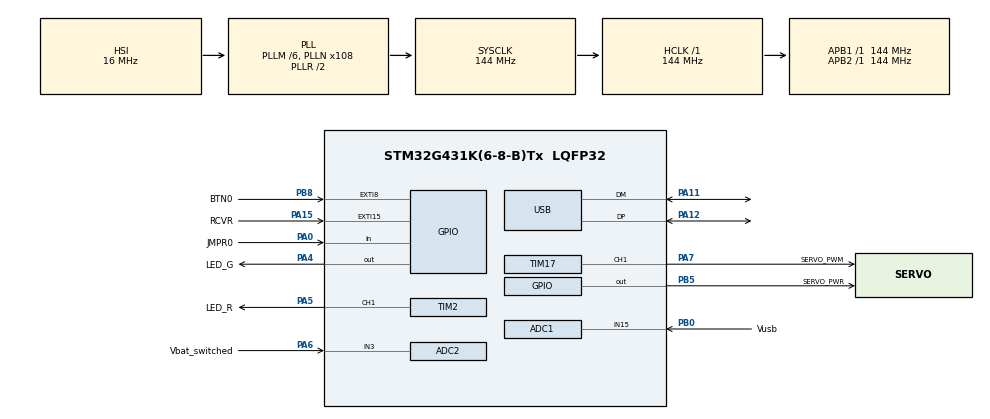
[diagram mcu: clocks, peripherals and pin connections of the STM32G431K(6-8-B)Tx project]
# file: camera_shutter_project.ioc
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ADC1.Channel-0\#ChannelRegularConversion=ADC_CHANNEL_15
ADC1.NbrOfConversionFlag=1
ADC1.OffsetNumber-0\#ChannelRegularConversion=ADC_OFFSET_NONE
ADC1.Rank-0\#ChannelRegularConversion=1
ADC1.SamplingTime-0\#ChannelRegularConversion=ADC_SAMPLETIME_2CYCLES_5
ADC1.master=1
ADC2.Channel-0\#ChannelRegularConversion=ADC_CHANNEL_3
ADC2.ClockPrescaler=ADC_CLOCK_SYNC_PCLK_DIV4
ADC2.NbrOfConversionFlag=1
ADC2.OffsetNumber-0\#ChannelRegularConversion=ADC_OFFSET_NONE
ADC2.Rank-0\#ChannelRegularConversion=1
ADC2.SamplingTime-0\#ChannelRegularConversion=ADC_SAMPLETIME_2CYCLES_5
Mcu.Family=STM32G4
Mcu.Name=STM32G431K(6-8-B)Tx
Mcu.Package=LQFP32
NVIC.EXTI15_10_IRQn=true\:3\:0\:true\:false\:true\:true\:true
NVIC.EXTI9_5_IRQn=true\:4\:0\:true\:false\:true\:true\:true
NVIC.PriorityGroup=NVIC_PRIORITYGROUP_4
NVIC.TIM1_CC_IRQn=true\:1\:0\:true\:false\:true\:true\:true
NVIC.TIM1_UP_TIM16_IRQn=true\:2\:0\:true\:false\:true\:true\:true
NVIC.USB_LP_IRQn=true\:0\:0\:false\:false\:true\:false\:true
PA0.GPIO_Label=JMPR0
PA0.Signal=GPIO_Input
PA11.Mode=Device
PA11.Signal=USB_DM
PA12.Mode=Device
PA12.Signal=USB_DP
PA13.Mode=Serial_Wire
PA13.Signal=SYS_JTMS-SWDIO
PA14.Mode=Serial_Wire
PA14.Signal=SYS_JTCK-SWCLK
PA15.GPIO_Label=RCVR
PA15.GPIO_ModeDefaultEXTI=GPIO_MODE_IT_FALLING
PA15.Signal=GPXTI15
PA4.GPIO_Label=LED_G
PA4.Signal=GPIO_Output
PA5.GPIO_Label=LED_R
PA5.Signal=S_TIM2_CH1
PA6.GPIO_Label=Vbat_switched
PA6.Mode=IN3-Single-Ended
PA6.Signal=ADC2_IN3
PA7.GPIO_Label=SERVO_PWM
PA7.Signal=S_TIM17_CH1
PB0.GPIO_Label=Vusb
PB0.Mode=IN15-Single-Ended
PB0.Signal=ADC1_IN15
PB5.GPIO_Label=SERVO_PWR
PB5.Signal=GPIO_Output
PB8-BOOT0.GPIO_Label=BTN0
PB8-BOOT0.GPIO_PuPd=GPIO_PULLDOWN
PB8-BOOT0.Signal=GPXTI8
PF0-OSC_IN.Mode=HSE-External-Oscillator
PF0-OSC_IN.Signal=RCC_OSC_IN
PF1-OSC_OUT.Mode=HSE-External-Oscillator
PF1-OSC_OUT.Signal=RCC_OSC_OUT
ProjectManager.HeapSize=0x200
ProjectManager.StackSize=0x400
ProjectManager.TargetToolchain=STM32CubeIDE
RCC.ADC12Freq_Value=144000000
RCC.AHBFreq_Value=144000000
RCC.APB1Freq_Value=144000000
RCC.APB1TimFreq_Value=144000000
RCC.APB2Freq_Value=144000000
RCC.APB2TimFreq_Value=144000000
RCC.CortexFreq_Value=144000000
RCC.EXTERNAL_CLOCK_VALUE=12288000
RCC.HCLKFreq_Value=144000000
RCC.HSE_VALUE=24000000
RCC.HSI48_VALUE=48000000
RCC.HSI_VALUE=16000000
RCC.LSE_VALUE=32768
RCC.PLLM=RCC_PLLM_DIV6
RCC.PLLN=108
RCC.PLLQ=RCC_PLLQ_DIV6
RCC.SYSCLKFreq_VALUE=144000000
RCC.SYSCLKSource=RCC_SYSCLKSOURCE_PLLCLK
RCC.USBFreq_Value=48000000
RCC.VCOOutputFreq_Value=288000000
SH.S_TIM17_CH1.0=TIM17_CH1,PWM Generation1 CH1
SH.S_TIM2_CH1.0=TIM2_CH1,PWM Generation1 CH1
TIM1.Channel-Output\ Compare1\ No\ Output=TIM_CHANNEL_1
TIM1.PeriodNoDither=1001
TIM1.Prescaler=146
TIM1.PulseNoDither_1=200
TIM1.RepetitionCounter=63
TIM1.TIM_MasterOutputTrigger=TIM_TRGO_RESET
TIM1.TIM_MasterSlaveMode=TIM_MASTERSLAVEMODE_DISABLE
TIM17.Channel=TIM_CHANNEL_1
TIM17.PeriodNoDither=2040
TIM17.Prescaler=143
TIM17.PulseNoDither_1=549
TIM2.Channel-PWM\ Generation1\ CH1=TIM_CHANNEL_1
TIM2.PeriodNoDither=9999
TIM2.Prescaler=9999
TIM2.PulseNoDither_1=4999
USB_DEVICE.CLASS_NAME_FS=CDC
USB_DEVICE.USBD_SELF_POWERED=1
USB_DEVICE.VirtualMode=Cdc
USB_DEVICE.VirtualModeFS=Cdc_FS
VP_SYS_VS_DBSignals.Mode=DisableDeadBatterySignals
VP_TIM17_VS_ClockSourceINT.Mode=Enable_Timer
VP_TIM1_VS_ClockSourceINT.Mode=Internal
VP_TIM1_VS_OPM.Mode=OPM_bit
VP_TIM1_VS_no_output1.Mode=Output Compare1 No Output
VP_TIM2_VS_ClockSourceINT.Mode=Internal
VP_USB_DEVICE_VS_USB_DEVICE_CDC_FS.Mode=CDC_FS
board=custom

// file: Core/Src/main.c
/* USER CODE BEGIN Header */
/**
  ******************************************************************************
  * @file           : main.c
  * @brief          : Main program body
  ******************************************************************************
  * @attention
  *
  * <h2><center>&copy; Copyright (c) 2021 STMicroelectronics.
  * All rights reserved.</center></h2>
  *
  * This software component is licensed by ST under BSD 3-Clause license,
  * the "License"; You may not use this file except in compliance with the
  * License. You may obtain a copy of the License at:
  *                        opensource.org/licenses/BSD-3-Clause
  *
  ******************************************************************************
  */
/* USER CODE END Header */
#include "main.h"
#include "usb_device.h"

/* USER CODE BEGIN Includes */
#include "program_logic.h"
#include "battery_tracking.h"
/* USER CODE END Includes */

ADC_HandleTypeDef hadc1;
ADC_HandleTypeDef hadc2;

TIM_HandleTypeDef htim1;
TIM_HandleTypeDef htim2;
TIM_HandleTypeDef htim17;

void SystemClock_Config(void);
static void MX_GPIO_Init(void);
static void MX_TIM2_Init(void);
static void MX_ADC2_Init(void);
static void MX_TIM1_Init(void);
static void MX_TIM17_Init(void);
static void MX_ADC1_Init(void);

int main(void)
{

  /* MCU Configuration--------------------------------------------------------*/

  /* Reset of all peripherals, Initializes the Flash interface and the Systick. */
  HAL_Init();

  /* Configure the system clock */
  SystemClock_Config();

  /* Initialize all configured peripherals */
  MX_GPIO_Init();
  MX_TIM2_Init();
  MX_ADC2_Init();
  MX_USB_Device_Init();
  MX_TIM1_Init();
  MX_TIM17_Init();
  MX_ADC1_Init();
  /* USER CODE BEGIN 2 */
  ProgramLogicInit();
  /* USER CODE END 2 */

  /* Infinite loop */
  while (1)
  {

    /* USER CODE BEGIN 3 */
    static int i = 0;
    printf("loop iteration: %d\n\n", i);
    HAL_Delay(500);
    BatteryTrackingUpdate();
    i++;
    HAL_Delay(500);
  }
  /* USER CODE END 3 */
}

void SystemClock_Config(void)
{
  RCC_OscInitTypeDef RCC_OscInitStruct = {0};
  RCC_ClkInitTypeDef RCC_ClkInitStruct = {0};
  RCC_PeriphCLKInitTypeDef PeriphClkInit = {0};

  /** Configure the main internal regulator output voltage
  */
  HAL_PWREx_ControlVoltageScaling(PWR_REGULATOR_VOLTAGE_SCALE1);
  /** Initializes the RCC Oscillators according to the specified parameters
  * in the RCC_OscInitTypeDef structure.
  */
  RCC_OscInitStruct.OscillatorType = RCC_OSCILLATORTYPE_HSI;
  RCC_OscInitStruct.HSIState = RCC_HSI_ON;
  RCC_OscInitStruct.HSICalibrationValue = RCC_HSICALIBRATION_DEFAULT;
  RCC_OscInitStruct.PLL.PLLState = RCC_PLL_ON;
  RCC_OscInitStruct.PLL.PLLSource = RCC_PLLSOURCE_HSI;
  RCC_OscInitStruct.PLL.PLLM = RCC_PLLM_DIV6;
  RCC_OscInitStruct.PLL.PLLN = 108;
  RCC_OscInitStruct.PLL.PLLP = RCC_PLLP_DIV2;
  RCC_OscInitStruct.PLL.PLLQ = RCC_PLLQ_DIV6;
  RCC_OscInitStruct.PLL.PLLR = RCC_PLLR_DIV2;
  if (HAL_RCC_OscConfig(&RCC_OscInitStruct) != HAL_OK)
  {
    Error_Handler();
  }
  /** Initializes the CPU, AHB and APB buses clocks
  */
  RCC_ClkInitStruct.ClockType = RCC_CLOCKTYPE_HCLK|RCC_CLOCKTYPE_SYSCLK
                              |RCC_CLOCKTYPE_PCLK1|RCC_CLOCKTYPE_PCLK2;
  RCC_ClkInitStruct.SYSCLKSource = RCC_SYSCLKSOURCE_PLLCLK;
  RCC_ClkInitStruct.AHBCLKDivider = RCC_SYSCLK_DIV1;
  RCC_ClkInitStruct.APB1CLKDivider = RCC_HCLK_DIV1;
  RCC_ClkInitStruct.APB2CLKDivider = RCC_HCLK_DIV1;

  if (HAL_RCC_ClockConfig(&RCC_ClkInitStruct, FLASH_LATENCY_4) != HAL_OK)
  {
    Error_Handler();
  }
  /** Initializes the peripherals clocks
  */
  PeriphClkInit.PeriphClockSelection = RCC_PERIPHCLK_USB|RCC_PERIPHCLK_ADC12;
  PeriphClkInit.UsbClockSelection = RCC_USBCLKSOURCE_PLL;
  PeriphClkInit.Adc12ClockSelection = RCC_ADC12CLKSOURCE_SYSCLK;
  if (HAL_RCCEx_PeriphCLKConfig(&PeriphClkInit) != HAL_OK)
  {
    Error_Handler();
  }
}

static void MX_ADC1_Init(void)
{

  ADC_MultiModeTypeDef multimode = {0};
  ADC_ChannelConfTypeDef sConfig = {0};

  /** Common config
  */
  hadc1.Instance = ADC1;
  hadc1.Init.ClockPrescaler = ADC_CLOCK_SYNC_PCLK_DIV4;
  hadc1.Init.Resolution = ADC_RESOLUTION_12B;
  hadc1.Init.DataAlign = ADC_DATAALIGN_RIGHT;
  hadc1.Init.GainCompensation = 0;
  hadc1.Init.ScanConvMode = ADC_SCAN_DISABLE;
  hadc1.Init.EOCSelection = ADC_EOC_SINGLE_CONV;
  hadc1.Init.LowPowerAutoWait = DISABLE;
  hadc1.Init.ContinuousConvMode = DISABLE;
  hadc1.Init.NbrOfConversion = 1;
  hadc1.Init.DiscontinuousConvMode = DISABLE;
  hadc1.Init.ExternalTrigConv = ADC_SOFTWARE_START;
  hadc1.Init.ExternalTrigConvEdge = ADC_EXTERNALTRIGCONVEDGE_NONE;
  hadc1.Init.DMAContinuousRequests = DISABLE;
  hadc1.Init.Overrun = ADC_OVR_DATA_PRESERVED;
  hadc1.Init.OversamplingMode = DISABLE;
  if (HAL_ADC_Init(&hadc1) != HAL_OK)
  {
    Error_Handler();
  }
  /** Configure the ADC multi-mode
  */
  multimode.Mode = ADC_MODE_INDEPENDENT;
  if (HAL_ADCEx_MultiModeConfigChannel(&hadc1, &multimode) != HAL_OK)
  {
    Error_Handler();
  }
  /** Configure Regular Channel
  */
  sConfig.Channel = ADC_CHANNEL_15;
  sConfig.Rank = ADC_REGULAR_RANK_1;
  sConfig.SamplingTime = ADC_SAMPLETIME_2CYCLES_5;
  sConfig.SingleDiff = ADC_SINGLE_ENDED;
  sConfig.OffsetNumber = ADC_OFFSET_NONE;
  sConfig.Offset = 0;
  if (HAL_ADC_ConfigChannel(&hadc1, &sConfig) != HAL_OK)
  {
    Error_Handler();
  }

}

static void MX_ADC2_Init(void)
{

  ADC_ChannelConfTypeDef sConfig = {0};

  /** Common config
  */
  hadc2.Instance = ADC2;
  hadc2.Init.ClockPrescaler = ADC_CLOCK_SYNC_PCLK_DIV4;
  hadc2.Init.Resolution = ADC_RESOLUTION_12B;
  hadc2.Init.DataAlign = ADC_DATAALIGN_RIGHT;
  hadc2.Init.GainCompensation = 0;
  hadc2.Init.ScanConvMode = ADC_SCAN_DISABLE;
  hadc2.Init.EOCSelection = ADC_EOC_SINGLE_CONV;
  hadc2.Init.LowPowerAutoWait = DISABLE;
  hadc2.Init.ContinuousConvMode = DISABLE;
  hadc2.Init.NbrOfConversion = 1;
  hadc2.Init.DiscontinuousConvMode = DISABLE;
  hadc2.Init.ExternalTrigConv = ADC_SOFTWARE_START;
  hadc2.Init.ExternalTrigConvEdge = ADC_EXTERNALTRIGCONVEDGE_NONE;
  hadc2.Init.DMAContinuousRequests = DISABLE;
  hadc2.Init.Overrun = ADC_OVR_DATA_PRESERVED;
  hadc2.Init.OversamplingMode = DISABLE;
  if (HAL_ADC_Init(&hadc2) != HAL_OK)
  {
    Error_Handler();
  }
  /** Configure Regular Channel
  */
  sConfig.Channel = ADC_CHANNEL_3;
  sConfig.Rank = ADC_REGULAR_RANK_1;
  sConfig.SamplingTime = ADC_SAMPLETIME_2CYCLES_5;
  sConfig.SingleDiff = ADC_SINGLE_ENDED;
  sConfig.OffsetNumber = ADC_OFFSET_NONE;
  sConfig.Offset = 0;
  if (HAL_ADC_ConfigChannel(&hadc2, &sConfig) != HAL_OK)
  {
    Error_Handler();
  }

}

static void MX_TIM1_Init(void)
{

  TIM_ClockConfigTypeDef sClockSourceConfig = {0};
  TIM_MasterConfigTypeDef sMasterConfig = {0};
  TIM_OC_InitTypeDef sConfigOC = {0};
  TIM_BreakDeadTimeConfigTypeDef sBreakDeadTimeConfig = {0};

  htim1.Instance = TIM1;
  htim1.Init.Prescaler = 146;
  htim1.Init.CounterMode = TIM_COUNTERMODE_UP;
  htim1.Init.Period = 1001;
  htim1.Init.ClockDivision = TIM_CLOCKDIVISION_DIV1;
  htim1.Init.RepetitionCounter = 63;
  htim1.Init.AutoReloadPreload = TIM_AUTORELOAD_PRELOAD_DISABLE;
  if (HAL_TIM_Base_Init(&htim1) != HAL_OK)
  {
    Error_Handler();
  }
  sClockSourceConfig.ClockSource = TIM_CLOCKSOURCE_INTERNAL;
  if (HAL_TIM_ConfigClockSource(&htim1, &sClockSourceConfig) != HAL_OK)
  {
    Error_Handler();
  }
  if (HAL_TIM_OC_Init(&htim1) != HAL_OK)
  {
    Error_Handler();
  }
  if (HAL_TIM_OnePulse_Init(&htim1, TIM_OPMODE_SINGLE) != HAL_OK)
  {
    Error_Handler();
  }
  sMasterConfig.MasterOutputTrigger = TIM_TRGO_RESET;
  sMasterConfig.MasterOutputTrigger2 = TIM_TRGO2_RESET;
  sMasterConfig.MasterSlaveMode = TIM_MASTERSLAVEMODE_DISABLE;
  if (HAL_TIMEx_MasterConfigSynchronization(&htim1, &sMasterConfig) != HAL_OK)
  {
    Error_Handler();
  }
  sConfigOC.OCMode = TIM_OCMODE_TIMING;
  sConfigOC.Pulse = 200;
  sConfigOC.OCPolarity = TIM_OCPOLARITY_HIGH;
  sConfigOC.OCNPolarity = TIM_OCNPOLARITY_HIGH;
  sConfigOC.OCFastMode = TIM_OCFAST_DISABLE;
  sConfigOC.OCIdleState = TIM_OCIDLESTATE_RESET;
  sConfigOC.OCNIdleState = TIM_OCNIDLESTATE_RESET;
  if (HAL_TIM_OC_ConfigChannel(&htim1, &sConfigOC, TIM_CHANNEL_1) != HAL_OK)
  {
    Error_Handler();
  }
  sBreakDeadTimeConfig.OffStateRunMode = TIM_OSSR_DISABLE;
  sBreakDeadTimeConfig.OffStateIDLEMode = TIM_OSSI_DISABLE;
  sBreakDeadTimeConfig.LockLevel = TIM_LOCKLEVEL_OFF;
  sBreakDeadTimeConfig.DeadTime = 0;
  sBreakDeadTimeConfig.BreakState = TIM_BREAK_DISABLE;
  sBreakDeadTimeConfig.BreakPolarity = TIM_BREAKPOLARITY_HIGH;
  sBreakDeadTimeConfig.BreakFilter = 0;
  sBreakDeadTimeConfig.BreakAFMode = TIM_BREAK_AFMODE_INPUT;
  sBreakDeadTimeConfig.Break2State = TIM_BREAK2_DISABLE;
  sBreakDeadTimeConfig.Break2Polarity = TIM_BREAK2POLARITY_HIGH;
  sBreakDeadTimeConfig.Break2Filter = 0;
  sBreakDeadTimeConfig.Break2AFMode = TIM_BREAK_AFMODE_INPUT;
  sBreakDeadTimeConfig.AutomaticOutput = TIM_AUTOMATICOUTPUT_DISABLE;
  if (HAL_TIMEx_ConfigBreakDeadTime(&htim1, &sBreakDeadTimeConfig) != HAL_OK)
  {
    Error_Handler();
  }

}

static void MX_TIM2_Init(void)
{

  TIM_ClockConfigTypeDef sClockSourceConfig = {0};
  TIM_MasterConfigTypeDef sMasterConfig = {0};
  TIM_OC_InitTypeDef sConfigOC = {0};

  htim2.Instance = TIM2;
  htim2.Init.Prescaler = 9999;
  htim2.Init.CounterMode = TIM_COUNTERMODE_UP;
  htim2.Init.Period = 9999;
  htim2.Init.ClockDivision = TIM_CLOCKDIVISION_DIV1;
  htim2.Init.AutoReloadPreload = TIM_AUTORELOAD_PRELOAD_DISABLE;
  if (HAL_TIM_Base_Init(&htim2) != HAL_OK)
  {
    Error_Handler();
  }
  sClockSourceConfig.ClockSource = TIM_CLOCKSOURCE_INTERNAL;
  if (HAL_TIM_ConfigClockSource(&htim2, &sClockSourceConfig) != HAL_OK)
  {
    Error_Handler();
  }
  if (HAL_TIM_PWM_Init(&htim2) != HAL_OK)
  {
    Error_Handler();
  }
  sMasterConfig.MasterOutputTrigger = TIM_TRGO_RESET;
  sMasterConfig.MasterSlaveMode = TIM_MASTERSLAVEMODE_DISABLE;
  if (HAL_TIMEx_MasterConfigSynchronization(&htim2, &sMasterConfig) != HAL_OK)
  {
    Error_Handler();
  }
  sConfigOC.OCMode = TIM_OCMODE_PWM1;
  sConfigOC.Pulse = 4999;
  sConfigOC.OCPolarity = TIM_OCPOLARITY_HIGH;
  sConfigOC.OCFastMode = TIM_OCFAST_DISABLE;
  if (HAL_TIM_PWM_ConfigChannel(&htim2, &sConfigOC, TIM_CHANNEL_1) != HAL_OK)
  {
    Error_Handler();
  }
  HAL_TIM_MspPostInit(&htim2);

}

static void MX_TIM17_Init(void)
{

  TIM_OC_InitTypeDef sConfigOC = {0};
  TIM_BreakDeadTimeConfigTypeDef sBreakDeadTimeConfig = {0};

  htim17.Instance = TIM17;
  htim17.Init.Prescaler = 143;
  htim17.Init.CounterMode = TIM_COUNTERMODE_UP;
  htim17.Init.Period = 2040;
  htim17.Init.ClockDivision = TIM_CLOCKDIVISION_DIV1;
  htim17.Init.RepetitionCounter = 0;
  htim17.Init.AutoReloadPreload = TIM_AUTORELOAD_PRELOAD_DISABLE;
  if (HAL_TIM_Base_Init(&htim17) != HAL_OK)
  {
    Error_Handler();
  }
  if (HAL_TIM_PWM_Init(&htim17) != HAL_OK)
  {
    Error_Handler();
  }
  sConfigOC.OCMode = TIM_OCMODE_PWM1;
  sConfigOC.Pulse = 549;
  sConfigOC.OCPolarity = TIM_OCPOLARITY_HIGH;
  sConfigOC.OCNPolarity = TIM_OCNPOLARITY_HIGH;
  sConfigOC.OCFastMode = TIM_OCFAST_DISABLE;
  sConfigOC.OCIdleState = TIM_OCIDLESTATE_RESET;
  sConfigOC.OCNIdleState = TIM_OCNIDLESTATE_RESET;
  if (HAL_TIM_PWM_ConfigChannel(&htim17, &sConfigOC, TIM_CHANNEL_1) != HAL_OK)
  {
    Error_Handler();
  }
  sBreakDeadTimeConfig.OffStateRunMode = TIM_OSSR_DISABLE;
  sBreakDeadTimeConfig.OffStateIDLEMode = TIM_OSSI_DISABLE;
  sBreakDeadTimeConfig.LockLevel = TIM_LOCKLEVEL_OFF;
  sBreakDeadTimeConfig.DeadTime = 0;
  sBreakDeadTimeConfig.BreakState = TIM_BREAK_DISABLE;
  sBreakDeadTimeConfig.BreakPolarity = TIM_BREAKPOLARITY_HIGH;
  sBreakDeadTimeConfig.BreakFilter = 0;
  sBreakDeadTimeConfig.AutomaticOutput = TIM_AUTOMATICOUTPUT_DISABLE;
  if (HAL_TIMEx_ConfigBreakDeadTime(&htim17, &sBreakDeadTimeConfig) != HAL_OK)
  {
    Error_Handler();
  }
  HAL_TIM_MspPostInit(&htim17);

}

static void MX_GPIO_Init(void)
{
  GPIO_InitTypeDef GPIO_InitStruct = {0};

  /* GPIO Ports Clock Enable */
  __HAL_RCC_GPIOF_CLK_ENABLE();
  __HAL_RCC_GPIOG_CLK_ENABLE();
  __HAL_RCC_GPIOA_CLK_ENABLE();
  __HAL_RCC_GPIOB_CLK_ENABLE();

  /*Configure GPIO pin Output Level */
  HAL_GPIO_WritePin(LED_G_GPIO_Port, LED_G_Pin, GPIO_PIN_RESET);

  /*Configure GPIO pin Output Level */
  HAL_GPIO_WritePin(SERVO_PWR_GPIO_Port, SERVO_PWR_Pin, GPIO_PIN_RESET);

  /*Configure GPIO pin : PG10 */
  GPIO_InitStruct.Pin = GPIO_PIN_10;
  GPIO_InitStruct.Mode = GPIO_MODE_ANALOG;
  GPIO_InitStruct.Pull = GPIO_NOPULL;
  HAL_GPIO_Init(GPIOG, &GPIO_InitStruct);

  /*Configure GPIO pin : JMPR0_Pin */
  GPIO_InitStruct.Pin = JMPR0_Pin;
  GPIO_InitStruct.Mode = GPIO_MODE_INPUT;
  GPIO_InitStruct.Pull = GPIO_NOPULL;
  HAL_GPIO_Init(JMPR0_GPIO_Port, &GPIO_InitStruct);

  /*Configure GPIO pins : PA1 PA2 PA3 PA8
                           PA9 PA10 */
  GPIO_InitStruct.Pin = GPIO_PIN_1|GPIO_PIN_2|GPIO_PIN_3|GPIO_PIN_8
                          |GPIO_PIN_9|GPIO_PIN_10;
  GPIO_InitStruct.Mode = GPIO_MODE_ANALOG;
  GPIO_InitStruct.Pull = GPIO_NOPULL;
  HAL_GPIO_Init(GPIOA, &GPIO_InitStruct);

  /*Configure GPIO pin : LED_G_Pin */
  GPIO_InitStruct.Pin = LED_G_Pin;
  GPIO_InitStruct.Mode = GPIO_MODE_OUTPUT_PP;
  GPIO_InitStruct.Pull = GPIO_NOPULL;
  GPIO_InitStruct.Speed = GPIO_SPEED_FREQ_LOW;
  HAL_GPIO_Init(LED_G_GPIO_Port, &GPIO_InitStruct);

  /*Configure GPIO pin : RCVR_Pin */
  GPIO_InitStruct.Pin = RCVR_Pin;
  GPIO_InitStruct.Mode = GPIO_MODE_IT_FALLING;
  GPIO_InitStruct.Pull = GPIO_NOPULL;
  HAL_GPIO_Init(RCVR_GPIO_Port, &GPIO_InitStruct);

  /*Configure GPIO pins : PB3 PB4 PB6 PB7 */
  GPIO_InitStruct.Pin = GPIO_PIN_3|GPIO_PIN_4|GPIO_PIN_6|GPIO_PIN_7;
  GPIO_InitStruct.Mode = GPIO_MODE_ANALOG;
  GPIO_InitStruct.Pull = GPIO_NOPULL;
  HAL_GPIO_Init(GPIOB, &GPIO_InitStruct);

  /*Configure GPIO pin : SERVO_PWR_Pin */
  GPIO_InitStruct.Pin = SERVO_PWR_Pin;
  GPIO_InitStruct.Mode = GPIO_MODE_OUTPUT_PP;
  GPIO_InitStruct.Pull = GPIO_NOPULL;
  GPIO_InitStruct.Speed = GPIO_SPEED_FREQ_LOW;
  HAL_GPIO_Init(SERVO_PWR_GPIO_Port, &GPIO_InitStruct);

  /*Configure GPIO pin : BTN0_Pin */
  GPIO_InitStruct.Pin = BTN0_Pin;
  GPIO_InitStruct.Mode = GPIO_MODE_IT_RISING;
  GPIO_InitStruct.Pull = GPIO_PULLDOWN;
  HAL_GPIO_Init(BTN0_GPIO_Port, &GPIO_InitStruct);

  /* EXTI interrupt init*/
  HAL_NVIC_SetPriority(EXTI9_5_IRQn, 4, 0);
  HAL_NVIC_EnableIRQ(EXTI9_5_IRQn);

  HAL_NVIC_SetPriority(EXTI15_10_IRQn, 3, 0);
  HAL_NVIC_EnableIRQ(EXTI15_10_IRQn);

}

void Error_Handler(void)
{
}

/************************ (C) COPYRIGHT STMicroelectronics *****END OF FILE****/
